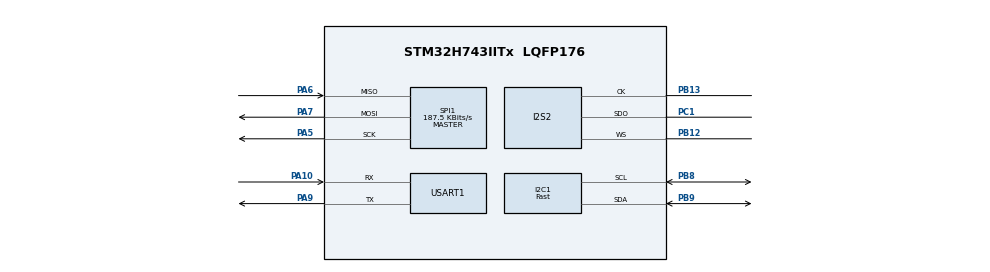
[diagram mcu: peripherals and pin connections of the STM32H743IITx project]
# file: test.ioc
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I2C1.I2C_Speed_Mode=I2C_Fast
I2C1.Timing=0x00B03FDB
I2S2.AudioFreq=I2S_AUDIOFREQ_44K
I2S2.ErrorAudioFreq=0.26 %
I2S2.Instance=SPI$Index
I2S2.RealAudioFreq=44.117 KHz
Mcu.Family=STM32H7
Mcu.Name=STM32H743IITx
Mcu.Package=LQFP176
NVIC.I2C1_ER_IRQn=true\:0\:0\:false\:false\:true\:true\:true
NVIC.I2C1_EV_IRQn=true\:0\:0\:false\:false\:true\:true\:true
NVIC.PriorityGroup=NVIC_PRIORITYGROUP_4
NVIC.SPI1_IRQn=true\:0\:0\:false\:false\:true\:true\:true
NVIC.SPI2_IRQn=true\:0\:0\:false\:false\:true\:true\:true
PA10.Mode=Asynchronous
PA10.Signal=USART1_RX
PA13\ (JTMS/SWDIO).Mode=JTAG_4_pins
PA13\ (JTMS/SWDIO).Signal=DEBUG_JTMS-SWDIO
PA14\ (JTCK/SWCLK).Mode=JTAG_4_pins
PA14\ (JTCK/SWCLK).Signal=DEBUG_JTCK-SWCLK
PA15\ (JTDI).Mode=JTAG_4_pins
PA15\ (JTDI).Signal=DEBUG_JTDI
PA5.Mode=Full_Duplex_Master
PA5.Signal=SPI1_SCK
PA6.Mode=Full_Duplex_Master
PA6.Signal=SPI1_MISO
PA7.Mode=Full_Duplex_Master
PA7.Signal=SPI1_MOSI
PA9.Mode=Asynchronous
PA9.Signal=USART1_TX
PB12.Mode=Half_Duplex_Master_Tx
PB12.Signal=I2S2_WS
PB13.Mode=Half_Duplex_Master_Tx
PB13.Signal=I2S2_CK
PB3\ (JTDO/TRACESWO).Mode=JTAG_4_pins
PB3\ (JTDO/TRACESWO).Signal=DEBUG_JTDO-SWO
PB8.Mode=I2C
PB8.Signal=I2C1_SCL
PB9.Mode=I2C
PB9.Signal=I2C1_SDA
PC1.Mode=Half_Duplex_Master_Tx
PC1.Signal=I2S2_SDO
PC14-OSC32_IN\ (OSC32_IN).Mode=LSE-External-Oscillator
PC14-OSC32_IN\ (OSC32_IN).Signal=RCC_OSC32_IN
PC15-OSC32_OUT\ (OSC32_OUT).Mode=LSE-External-Oscillator
PC15-OSC32_OUT\ (OSC32_OUT).Signal=RCC_OSC32_OUT
PH0-OSC_IN\ (PH0).Mode=HSE-External-Oscillator
PH0-OSC_IN\ (PH0).Signal=RCC_OSC_IN
PH1-OSC_OUT\ (PH1).Mode=HSE-External-Oscillator
PH1-OSC_OUT\ (PH1).Signal=RCC_OSC_OUT
ProjectManager.HeapSize=0x1000
ProjectManager.StackSize=0x1000
ProjectManager.TargetToolchain=STM32CubeIDE
RCC.ADCCLockSelection=RCC_ADCCLKSOURCE_PLL3
RCC.ADCFreq_Value=8000000
RCC.APB1Freq_Value=120000000
RCC.APB2Freq_Value=120000000
RCC.APB3Freq_Value=120000000
RCC.APB4Freq_Value=120000000
RCC.CortexFreq_Value=480000000
RCC.D1PPRE=RCC_APB3_DIV2
RCC.D2PPRE1=RCC_APB1_DIV2
RCC.D2PPRE2=RCC_APB2_DIV2
RCC.D3PPRE=RCC_APB4_DIV2
RCC.DIVM1=4
RCC.DIVM2=4
RCC.DIVN1=60
RCC.DIVN2=9
RCC.DIVN3=120
RCC.DIVP2=1
RCC.DIVQ1=20
RCC.DIVR3=30
RCC.HCLKFreq_Value=240000000
RCC.HPRE=RCC_HCLK_DIV2
RCC.PLL2FRACN=3072
RCC.PLL3FRACN=0
RCC.PLLFRACN=0
RCC.PWR_Regulator_Voltage_Scale=PWR_REGULATOR_VOLTAGE_SCALE0
RCC.ProductRev=revV
RCC.SYSCLKFreq_VALUE=480000000
RCC.SYSCLKSource=RCC_SYSCLKSOURCE_PLLCLK
RCC.USBFreq_Value=48000000
SPI1.BaudRatePrescaler=SPI_BAUDRATEPRESCALER_256
SPI1.CalculateBaudRate=187.5 KBits/s
SPI1.DataSize=SPI_DATASIZE_8BIT
SPI1.Direction=SPI_DIRECTION_2LINES
SPI1.Mode=SPI_MODE_MASTER
SPI1.VirtualType=VM_MASTER
USART1.VirtualMode-Asynchronous=VM_ASYNC
board=custom

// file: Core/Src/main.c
/* USER CODE BEGIN Header */
/**
  ******************************************************************************
  * @file           : main.c
  * @brief          : Main program body
  ******************************************************************************
  * @attention
  *
  * Copyright (c) 2022 STMicroelectronics.
  * All rights reserved.
  *
  * This software is licensed under terms that can be found in the LICENSE file
  * in the root directory of this software component.
  * If no LICENSE file comes with this software, it is provided AS-IS.
  *
  ******************************************************************************
  */
/* USER CODE END Header */
#include "main.h"
#include "i2c.h"
#include "i2s.h"
#include "spi.h"
#include "usart.h"
#include "gpio.h"

/* USER CODE BEGIN Includes */
#include "BSP.h"
#include "Driver/DEBUG/debug.h"

#include "Driver/ADC_Data/ADC_Data.h"
/* USER CODE END Includes */

void SystemClock_Config(void);

int main(void)
{

  /* MCU Configuration--------------------------------------------------------*/

  /* Reset of all peripherals, Initializes the Flash interface and the Systick. */
  HAL_Init();

  /* Configure the system clock */
  SystemClock_Config();

  /* Initialize all configured peripherals */
  MX_GPIO_Init();
  MX_USART1_UART_Init();
  MX_I2C1_Init();
  MX_I2S2_Init();
  MX_SPI1_Init();
  /* USER CODE BEGIN 2 */
  User_BSP_Init();
  /* USER CODE END 2 */

  /* Infinite loop */
  /* USER CODE BEGIN WHILE */
  while (1)
  {
	  Driver_ADC_Test_Task();
    /* USER CODE END WHILE */

  }
}

void SystemClock_Config(void)
{
  RCC_OscInitTypeDef RCC_OscInitStruct = {0};
  RCC_ClkInitTypeDef RCC_ClkInitStruct = {0};

  /** Supply configuration update enable
  */
  HAL_PWREx_ConfigSupply(PWR_LDO_SUPPLY);
  /** Configure the main internal regulator output voltage
  */
  __HAL_PWR_VOLTAGESCALING_CONFIG(PWR_REGULATOR_VOLTAGE_SCALE0);

  while(!__HAL_PWR_GET_FLAG(PWR_FLAG_VOSRDY)) {}
  /** Initializes the RCC Oscillators according to the specified parameters
  * in the RCC_OscInitTypeDef structure.
  */
  RCC_OscInitStruct.OscillatorType = RCC_OSCILLATORTYPE_HSI;
  RCC_OscInitStruct.HSIState = RCC_HSI_DIV1;
  RCC_OscInitStruct.HSICalibrationValue = RCC_HSICALIBRATION_DEFAULT;
  RCC_OscInitStruct.PLL.PLLState = RCC_PLL_ON;
  RCC_OscInitStruct.PLL.PLLSource = RCC_PLLSOURCE_HSI;
  RCC_OscInitStruct.PLL.PLLM = 4;
  RCC_OscInitStruct.PLL.PLLN = 60;
  RCC_OscInitStruct.PLL.PLLP = 2;
  RCC_OscInitStruct.PLL.PLLQ = 20;
  RCC_OscInitStruct.PLL.PLLR = 2;
  RCC_OscInitStruct.PLL.PLLRGE = RCC_PLL1VCIRANGE_3;
  RCC_OscInitStruct.PLL.PLLVCOSEL = RCC_PLL1VCOWIDE;
  RCC_OscInitStruct.PLL.PLLFRACN = 0;
  if (HAL_RCC_OscConfig(&RCC_OscInitStruct) != HAL_OK)
  {
    Error_Handler();
  }
  /** Initializes the CPU, AHB and APB buses clocks
  */
  RCC_ClkInitStruct.ClockType = RCC_CLOCKTYPE_HCLK|RCC_CLOCKTYPE_SYSCLK
                              |RCC_CLOCKTYPE_PCLK1|RCC_CLOCKTYPE_PCLK2
                              |RCC_CLOCKTYPE_D3PCLK1|RCC_CLOCKTYPE_D1PCLK1;
  RCC_ClkInitStruct.SYSCLKSource = RCC_SYSCLKSOURCE_PLLCLK;
  RCC_ClkInitStruct.SYSCLKDivider = RCC_SYSCLK_DIV1;
  RCC_ClkInitStruct.AHBCLKDivider = RCC_HCLK_DIV2;
  RCC_ClkInitStruct.APB3CLKDivider = RCC_APB3_DIV2;
  RCC_ClkInitStruct.APB1CLKDivider = RCC_APB1_DIV2;
  RCC_ClkInitStruct.APB2CLKDivider = RCC_APB2_DIV2;
  RCC_ClkInitStruct.APB4CLKDivider = RCC_APB4_DIV2;

  if (HAL_RCC_ClockConfig(&RCC_ClkInitStruct, FLASH_LATENCY_4) != HAL_OK)
  {
    Error_Handler();
  }
}

void Error_Handler(void)
{
  __disable_irq();
  while (1)
  {
  }
}
